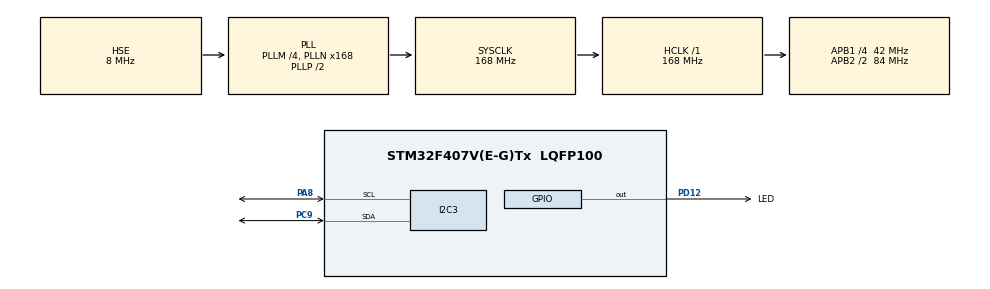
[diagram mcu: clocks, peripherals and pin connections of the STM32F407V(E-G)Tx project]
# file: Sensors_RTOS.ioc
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Mcu.Family=STM32F4
RCC.PLLSourceVirtual=RCC_PLLSOURCE_HSE
I2C3.I2C_Mode=I2C_Standard
PD12.GPIO_Label=LED
PH0-OSC_IN.Signal=RCC_OSC_IN
RCC.CortexFreq_Value=168000000
PD12.GPIO_Speed=GPIO_SPEED_FREQ_LOW
FREERTOS.Tasks01=Util,24,128,StartUtil,Default,NULL,Dynamic,NULL,NULL;Sensor,24,128,StartSensor,Default,NULL,Dynamic,NULL,NULL
RCC.APB1CLKDivider=RCC_HCLK_DIV4
RCC.SYSCLKSource=RCC_SYSCLKSOURCE_PLLCLK
ProjectManager.StackSize=0x400
VP_FREERTOS_VS_CMSIS_V2.Mode=CMSIS_V2
PA13.Signal=SYS_JTMS-SWDIO
ProjectManager.TargetToolchain=STM32CubeIDE
RCC.HCLKFreq_Value=168000000
RCC.APB2TimFreq_Value=168000000
RCC.LSE_VALUE=32768
RCC.AHBFreq_Value=168000000
PH0-OSC_IN.Mode=HSE-External-Oscillator
RCC.HSE_VALUE=8000000
board=custom
RCC.VCOOutputFreq_Value=336000000
NVIC.I2C3_EV_IRQn=true\:5\:0\:false\:false\:true\:true\:true\:true
RCC.APB2Freq_Value=84000000
PA14.Mode=Serial_Wire
VP_SYS_VS_tim1.Mode=TIM1
PC9.Mode=I2C
PH1-OSC_OUT.Signal=RCC_OSC_OUT
PA8.Signal=I2C3_SCL
PA13.Mode=Serial_Wire
Mcu.Name=STM32F407V(E-G)Tx
PH1-OSC_OUT.Mode=HSE-External-Oscillator
RCC.48MHZClocksFreq_Value=84000000
RCC.SYSCLKFreq_VALUE=168000000
Mcu.Package=LQFP100
NVIC.TimeBase=TIM1_UP_TIM10_IRQn
PD12.Signal=GPIO_Output
NVIC.TimeBaseIP=TIM1
PA14.Signal=SYS_JTCK-SWCLK
ProjectManager.HeapSize=0x200
NVIC.TIM1_UP_TIM10_IRQn=true\:0\:0\:false\:false\:true\:false\:false\:true
RCC.HSI_VALUE=16000000
NVIC.PriorityGroup=NVIC_PRIORITYGROUP_4
RCC.APB2CLKDivider=RCC_HCLK_DIV2
RCC.PLLM=4
NVIC.I2C3_ER_IRQn=true\:5\:0\:false\:false\:true\:true\:true\:true
RCC.PLLN=168
RCC.APB1TimFreq_Value=84000000
PA8.Mode=I2C
PC9.Signal=I2C3_SDA
RCC.APB1Freq_Value=42000000

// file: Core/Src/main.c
/* USER CODE BEGIN Header */
/**
  ******************************************************************************
  * @file           : main.c
  * @brief          : Main program body
  ******************************************************************************
  * @attention
  *
  * <h2><center>&copy; Copyright (c) 2021 STMicroelectronics.
  * All rights reserved.</center></h2>
  *
  * This software component is licensed by ST under BSD 3-Clause license,
  * the "License"; You may not use this file except in compliance with the
  * License. You may obtain a copy of the License at:
  *                        opensource.org/licenses/BSD-3-Clause
  *
  ******************************************************************************
  */
/* USER CODE END Header */
#include "main.h"
#include "cmsis_os.h"

/* USER CODE BEGIN Includes */
#include "LIS3MDL.h"
/* USER CODE END Includes */

/* USER CODE BEGIN PTD */
LIS3MDL_t sensor;
/* USER CODE END PTD */

/* USER CODE BEGIN PD */
#define SENSOR_REFRESH_RATE 100
#define UTIL_REFRESH_RATE	100
/* USER CODE END PD */

I2C_HandleTypeDef hi2c3;

/* Definitions for Util */
osThreadId_t UtilHandle;
const osThreadAttr_t Util_attributes = {
  .name = "Util",
  .stack_size = 128 * 4,
  .priority = (osPriority_t) osPriorityNormal,
};
/* Definitions for Sensor */
osThreadId_t SensorHandle;
const osThreadAttr_t Sensor_attributes = {
  .name = "Sensor",
  .stack_size = 128 * 4,
  .priority = (osPriority_t) osPriorityNormal,
};
/* USER CODE BEGIN PV */
float magValue[3];
float temp;
/* USER CODE END PV */

void SystemClock_Config(void);
static void MX_GPIO_Init(void);
static void MX_I2C3_Init(void);
void StartUtil(void *argument);
void StartSensor(void *argument);

int main(void)
{

  /* MCU Configuration--------------------------------------------------------*/

  /* Reset of all peripherals, Initializes the Flash interface and the Systick. */
  HAL_Init();

  /* Configure the system clock */
  SystemClock_Config();

  /* Initialize all configured peripherals */
  MX_GPIO_Init();
  MX_I2C3_Init();

  /* Init scheduler */
  osKernelInitialize();

  /* Create the thread(s) */
  /* creation of Util */
  UtilHandle = osThreadNew(StartUtil, NULL, &Util_attributes);

  /* creation of Sensor */
  SensorHandle = osThreadNew(StartSensor, NULL, &Sensor_attributes);

  /* Start scheduler */
  osKernelStart();

  /* We should never get here as control is now taken by the scheduler */
  /* Infinite loop */
  while (1)
  {

  }
}

void SystemClock_Config(void)
{
  RCC_OscInitTypeDef RCC_OscInitStruct = {0};
  RCC_ClkInitTypeDef RCC_ClkInitStruct = {0};

  /** Configure the main internal regulator output voltage
  */
  __HAL_RCC_PWR_CLK_ENABLE();
  __HAL_PWR_VOLTAGESCALING_CONFIG(PWR_REGULATOR_VOLTAGE_SCALE1);
  /** Initializes the RCC Oscillators according to the specified parameters
  * in the RCC_OscInitTypeDef structure.
  */
  RCC_OscInitStruct.OscillatorType = RCC_OSCILLATORTYPE_HSE;
  RCC_OscInitStruct.HSEState = RCC_HSE_ON;
  RCC_OscInitStruct.PLL.PLLState = RCC_PLL_ON;
  RCC_OscInitStruct.PLL.PLLSource = RCC_PLLSOURCE_HSE;
  RCC_OscInitStruct.PLL.PLLM = 4;
  RCC_OscInitStruct.PLL.PLLN = 168;
  RCC_OscInitStruct.PLL.PLLP = RCC_PLLP_DIV2;
  RCC_OscInitStruct.PLL.PLLQ = 4;
  if (HAL_RCC_OscConfig(&RCC_OscInitStruct) != HAL_OK)
  {
    Error_Handler();
  }
  /** Initializes the CPU, AHB and APB buses clocks
  */
  RCC_ClkInitStruct.ClockType = RCC_CLOCKTYPE_HCLK|RCC_CLOCKTYPE_SYSCLK
                              |RCC_CLOCKTYPE_PCLK1|RCC_CLOCKTYPE_PCLK2;
  RCC_ClkInitStruct.SYSCLKSource = RCC_SYSCLKSOURCE_PLLCLK;
  RCC_ClkInitStruct.AHBCLKDivider = RCC_SYSCLK_DIV1;
  RCC_ClkInitStruct.APB1CLKDivider = RCC_HCLK_DIV4;
  RCC_ClkInitStruct.APB2CLKDivider = RCC_HCLK_DIV2;

  if (HAL_RCC_ClockConfig(&RCC_ClkInitStruct, FLASH_LATENCY_5) != HAL_OK)
  {
    Error_Handler();
  }
}

static void MX_I2C3_Init(void)
{

  hi2c3.Instance = I2C3;
  hi2c3.Init.ClockSpeed = 100000;
  hi2c3.Init.DutyCycle = I2C_DUTYCYCLE_2;
  hi2c3.Init.OwnAddress1 = 0;
  hi2c3.Init.AddressingMode = I2C_ADDRESSINGMODE_7BIT;
  hi2c3.Init.DualAddressMode = I2C_DUALADDRESS_DISABLE;
  hi2c3.Init.OwnAddress2 = 0;
  hi2c3.Init.GeneralCallMode = I2C_GENERALCALL_DISABLE;
  hi2c3.Init.NoStretchMode = I2C_NOSTRETCH_DISABLE;
  if (HAL_I2C_Init(&hi2c3) != HAL_OK)
  {
    Error_Handler();
  }

}

static void MX_GPIO_Init(void)
{
  GPIO_InitTypeDef GPIO_InitStruct = {0};

  /* GPIO Ports Clock Enable */
  __HAL_RCC_GPIOH_CLK_ENABLE();
  __HAL_RCC_GPIOD_CLK_ENABLE();
  __HAL_RCC_GPIOC_CLK_ENABLE();
  __HAL_RCC_GPIOA_CLK_ENABLE();

  /*Configure GPIO pin Output Level */
  HAL_GPIO_WritePin(LED_GPIO_Port, LED_Pin, GPIO_PIN_RESET);

  /*Configure GPIO pin : LED_Pin */
  GPIO_InitStruct.Pin = LED_Pin;
  GPIO_InitStruct.Mode = GPIO_MODE_OUTPUT_PP;
  GPIO_InitStruct.Pull = GPIO_NOPULL;
  GPIO_InitStruct.Speed = GPIO_SPEED_FREQ_LOW;
  HAL_GPIO_Init(LED_GPIO_Port, &GPIO_InitStruct);

}

void StartUtil(void *argument)
{
  /* USER CODE BEGIN 5 */

  /* Infinite loop */
  for(;;)
  {
	  magValue[0] = sensor.mag_raw[0];
	  magValue[1] = sensor.mag_raw[1];
	  magValue[2] = sensor.mag_raw[2];
	  temp = sensor.temp_raw;
	  osDelay(UTIL_REFRESH_RATE);
  }
  /* USER CODE END 5 */
}

void StartSensor(void *argument)
{
  /* USER CODE BEGIN StartSensor */
	LIS3MDL_Init(&sensor, &hi2c3, LIS3MDL_Device_0, LIS3MDL_Scale_4G, LIS3MDL_MODE_ULTRAHIGH, LIS3MDL_ODR_7);
  /* Infinite loop */
  for(;;)
  {
	  LIS3MDL_ReadMag(&sensor, &hi2c3);
	  osDelay(SENSOR_REFRESH_RATE);
  }
  /* USER CODE END StartSensor */
}

 /**
  * @brief  Period elapsed callback in non blocking mode
  * @note   This function is called  when TIM1 interrupt took place, inside
  * HAL_TIM_IRQHandler(). It makes a direct call to HAL_IncTick() to increment
  * a global variable "uwTick" used as application time base.
  * @param  htim : TIM handle
  * @retval None
  */
void HAL_TIM_PeriodElapsedCallback(TIM_HandleTypeDef *htim)
{
  if (htim->Instance == TIM1) {
    HAL_IncTick();
  }
}

void Error_Handler(void)
{
  __disable_irq();
  while (1)
  {
  }
}

/************************ (C) COPYRIGHT STMicroelectronics *****END OF FILE****/
